// Description: LIN Description file created using Vector's DaVinci Network Designer

// Created: 07 Sep 2007 15:20:26

// Author: Vector Informatik GmbH

// Version: 0.1

LIN_description_file;
LIN_protocol_version = "J2602_1_1.0";
LIN_language_version = "J2602_3_1.0";
LIN_speed = 10.417 kbps;

Nodes {
  Master: TurnControl, 1 ms, 0 ms , 48 bits, 40 %;
  Slaves: Left_TurnIndicator, Right_TurnIndicator ;
}

Signals {
  Left_APINFO0: 1, 0, Left_TurnIndicator, TurnControl ;
  Left_APINFO1: 1, 0, Left_TurnIndicator, TurnControl ;
  Left_APINFO2: 1, 0, Left_TurnIndicator, TurnControl ;
  Left_APINFO3: 1, 0, Left_TurnIndicator, TurnControl ;
  Left_APINFO4: 1, 1, Left_TurnIndicator, TurnControl ;
  Left_TurnIndication: 1, 0, TurnControl, Left_TurnIndicator ;
  Left_TurnIndicator_RespErr: 3, 0, Left_TurnIndicator, TurnControl ;
  Left_TurnIndicator_State: 1, 0, Left_TurnIndicator, TurnControl ;
  Right_APINFO0: 1, 0, Right_TurnIndicator, TurnControl ;
  Right_APINFO1: 1, 0, Right_TurnIndicator, TurnControl ;
  Right_APINFO2: 1, 0, Right_TurnIndicator, TurnControl ;
  Right_APINFO3: 1, 0, Right_TurnIndicator, TurnControl ;
  Right_APINFO4: 1, 0, Right_TurnIndicator, TurnControl ;
  Right_TurnIndication: 1, 0, TurnControl, Right_TurnIndicator ;
  Right_TurnIndicator_RespErr: 3, 0, Right_TurnIndicator, TurnControl ;
  Right_TurnIndicator_State: 1, 0, Right_TurnIndicator, TurnControl ;
  WarningLightIndication: 1, 0, TurnControl, Right_TurnIndicator, Left_TurnIndicator ;
}

Frames {
  LeftTurn: 4, TurnControl, 1 {
    Left_TurnIndication, 0 ;
  }
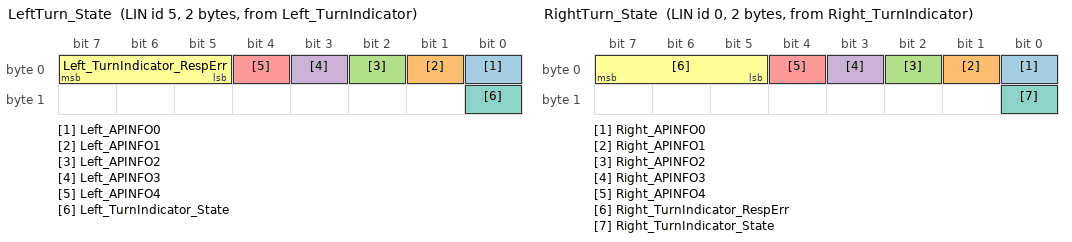
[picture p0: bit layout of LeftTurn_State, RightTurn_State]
  LeftTurn_State: 5, Left_TurnIndicator, 2 {
    Left_APINFO0, 0 ;
    Left_APINFO1, 1 ;
    Left_APINFO2, 2 ;
    Left_APINFO3, 3 ;
    Left_APINFO4, 4 ;
    Left_TurnIndicator_RespErr, 5 ;
    Left_TurnIndicator_State, 8 ;
  }
  RightTurn: 1, TurnControl, 1 {
    Right_TurnIndication, 0 ;
  }
  RightTurn_State: 0, Right_TurnIndicator, 2 {
    Right_APINFO0, 0 ;
    Right_APINFO1, 1 ;
    Right_APINFO2, 2 ;
    Right_APINFO3, 3 ;
    Right_APINFO4, 4 ;
    Right_TurnIndicator_RespErr, 5 ;
    Right_TurnIndicator_State, 8 ;
  }
  WarningLight: 56, TurnControl, 1 {
    WarningLightIndication, 0 ;
  }
}

Node_attributes {
  Left_TurnIndicator{
    LIN_protocol = "J2602_1_1.0" ;
    configured_NAD = 0x61 ;
    product_id = 0x1010, 0x1000, 0 ;
    response_error = Left_TurnIndicator_RespErr ;
    configurable_frames {
      LeftTurn = 0x4 ;
      LeftTurn_State = 0x5 ;
      WarningLight = 0x39 ;
    }
    response_tolerance = 40 %;
  }
  Right_TurnIndicator{
    LIN_protocol = "J2602_1_1.0" ;
    configured_NAD = 0x60 ;
    product_id = 0x1010, 0x1001, 0 ;
    response_error = Right_TurnIndicator_RespErr ;
    configurable_frames {
      RightTurn_State = 0x0 ;
    RightTurn = 0x1 ;
      WarningLight = 0x39 ;
    }
    response_tolerance = 40 %;
  }
}

Schedule_tables {
 TurnIndicationTable {
    LeftTurn delay 17 ms ;
    RightTurn delay 17 ms ;
    WarningLight delay 17 ms ;
    LeftTurn_State delay 17 ms ;
    RightTurn_State delay 17 ms ;
  }
 TargetedReset {
    FreeFormat { 0x61, 0x1, 0xb5, 0xff, 0xff, 0xff, 0xff, 0xff } delay 17 ms ;
    SlaveResp delay 17 ms ;
  }
 BroadcastReset {
    FreeFormat { 0x7F, 0x1, 0xb5, 0xff, 0xff, 0xff, 0xff, 0xff } delay 17 ms ;
    SlaveResp delay 17 ms ;
  }
}

Signal_encoding_types {
  SAEJ2602_Error {
    logical_value, 0, "No Detected Fault" ;
    logical_value, 1, "Reset" ;
    logical_value, 2, "Reserved" ;
    logical_value, 3, "Reserved" ;
    logical_value, 4, "Tx Bit Error" ;
    logical_value, 5, "Checksum Error" ;
    logical_value, 6, "Byte Field Framing Error" ;
    logical_value, 7, "ID Parity Error" ;
  }
  TurnIndication {
    logical_value, 0, "TurnOff" ;
    logical_value, 1, "TurnOn" ;
  }
}

Signal_representation {
  SAEJ2602_Error: Left_TurnIndicator_RespErr, Right_TurnIndicator_RespErr ;
  TurnIndication: Left_TurnIndication, Left_TurnIndicator_State, Right_TurnIndication, Right_TurnIndicator_State, WarningLightIndication ;
}
